# haltium_secure register map
Vendor: Nordic Semiconductor; Series: nRFHaltium; File version: 1
CPU: CM33 r0p4, little endian, MPU, FPU, 3 interrupt priority bits, 480 interrupts
Registers are 32-bit, read-write, reset 0x0 unless marked. A register's access mark holds for its fields unless they carry their own. Offsets are from the block's base; [hi:lo] are bit positions; lines under a group give offsets from that group; {n}, {i} and the like mark numbered series; 'fields as' and 'values as' point back to an identical list.

## CACHE0INFO_S — CACHEINFO 0
Base 0xE0F08000
Same registers: CACHE1INFO_S 0xE0F0C000
{0x0+8i} SET[{i}] (i=0..255) group — Unspecified
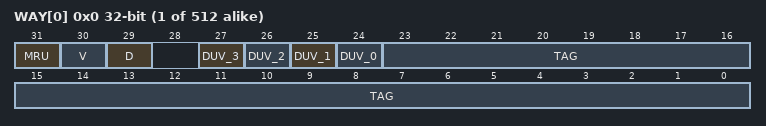
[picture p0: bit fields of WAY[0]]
  {0x0+4j} WAY[{j}] (j=0..1) — Description collection: Cache information for SET[n], WAY[o].
    [31] MRU ro — Most recently used way.
      0=Way0 was most recently used; 1=Way1 was most recently used
    [30] V ro — Line valid bit.
      0=Invalid cache line; 1=Valid cache line
    [29] D ro — Line dirty bit.
      0=Clean cache line; 1=Dirty cache line
    [n+24] DUV_{n} (n=0..3) — Data unit valid info.
      0=Invalid data unit; 1=Valid data unit
    [23:0] TAG — Cache tag.

## RAMC00_NS — RAM Controller 0
Base 0x41004000
Same registers: ROMC00_NS 0x41005000, RAMC00_S 0x51004000, ROMC00_S 0x51005000
0x100 EVENTS_ERRORFIX — ECC detected fixable (one bit) error in read data from RAM.
  [0] EVENTS_ERRORFIX
    0=NotGenerated (Event not generated); 1=Generated (Event generated)
0x104 EVENTS_ERRORNONFIX — ECC detected non-fixable (multiple bits) error in read data from RAM.
  [0] EVENTS_ERRORNONFIX
    values as EVENTS_ERRORFIX.EVENTS_ERRORFIX
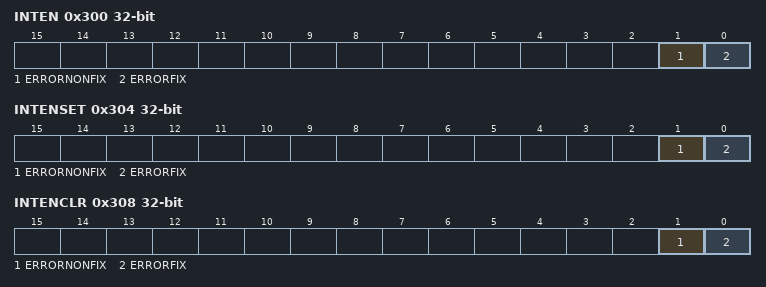
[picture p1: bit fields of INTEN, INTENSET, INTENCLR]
0x300 INTEN — Enable or disable interrupt
  [1] ERRORNONFIX — Enable or disable interrupt for event ERRORNONFIX
    0=Disabled; 1=Enabled
  [0] ERRORFIX — Enable or disable interrupt for event ERRORFIX
    0=Disabled; 1=Enabled
0x304 INTENSET — Enable interrupt
  [1] ERRORNONFIX — Write '1' to enable interrupt for event ERRORNONFIX
    on read: 0=Disabled (Read: Disabled); 1=Enabled (Read: Enabled) | on write: 1=Set (Enable)
  [0] ERRORFIX — Write '1' to enable interrupt for event ERRORFIX
    values as ERRORNONFIX
0x308 INTENCLR — Disable interrupt
  [1] ERRORNONFIX — Write '1' to disable interrupt for event ERRORNONFIX
    on read: 0=Disabled (Read: Disabled); 1=Enabled (Read: Enabled) | on write: 1=Clear (Disable)
  [0] ERRORFIX — Write '1' to disable interrupt for event ERRORFIX
    values as ERRORNONFIX
0x400 FIXADDR ro — Address of the last fixable error detected by the ECC.
  [31:0] ADDR — Address of the last fixable error.
0x404 NONFIXADDR ro — Address of the last non-fixable error detected by the ECC.
  [31:0] ADDR — Address of the last fixable error.
0x500 WAITSTATES — Waitstates for read.
  [2:0] WAITSTATES — Waitstates for read from RAM or ROM.
0x600 SECBASE — Base address for secure access area.
  [31:0] ADDR — Base address
0x604 SECENABLE — Enable secure access restrictions.
  [0] ENABLE — Enable secure access restrictions
    0=Disable (Secure access restrictions disabled); 1=Enable (Secure access restrictions enabled)

## CPUCONF_NS — CPU Configuration 0
Base 0x41011000
Same registers: CPUCONF_S 0x51011000
0x00 TASKS_ERASECACHE wo — Erase the caches used by the CPU.
  [0] TASKS_ERASECACHE
    1=Trigger task
0x500 INITSVTOR — Initial value of the secure VTOR (Vector Table Offset Register) after CPU reset.
  [31:0] INITSVTOR — Initial value of the VTOR.
0x504 INITNSVTOR — Initial value of the non-secure VTOR (Vector Table Offset Register).
  [31:0] INITNSVTOR — Initial value of the VTOR.
0x508 CPUSTART — Enable for starting the CPU
  [0] EN — Enable to start the CPU.
    0=Stopped (CPU stopped.); 1=Started (CPU started.)
0x50C CPUWAIT — Enable for the CPU wait.
  [0] EN — Enable to the CPU wait.
    0=Disabled (CPU is not waiting.); 1=Enabled (CPU is waiting.)

## TAMPC_S — Tamper controller
Base 0x51016000
0x100 EVENTS_TAMPER — Tamper controller detected an error.
  [0] EVENTS_TAMPER
    0=NotGenerated (Event not generated); 1=Generated (Event generated)
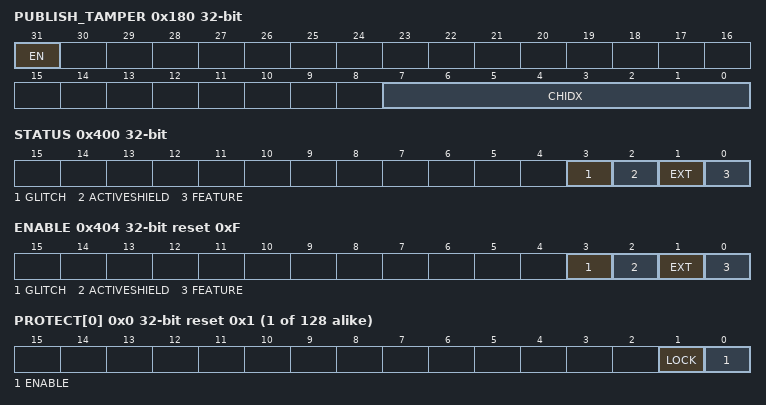
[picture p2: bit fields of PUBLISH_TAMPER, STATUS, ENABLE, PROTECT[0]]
0x180 PUBLISH_TAMPER — Publish configuration for event TAMPER
  [31] EN
    0=Disabled (Disable publishing); 1=Enabled (Enable publishing)
  [7:0] CHIDX — DPPI channel that event TAMPER will publish to
0x300 INTEN — Enable or disable interrupt
  [0] TAMPER — Enable or disable interrupt for event TAMPER
    0=Disabled; 1=Enabled
0x304 INTENSET — Enable interrupt
  [0] TAMPER — Write '1' to enable interrupt for event TAMPER
    on read: 0=Disabled (Read: Disabled); 1=Enabled (Read: Enabled) | on write: 1=Set (Enable)
0x308 INTENCLR — Disable interrupt
  [0] TAMPER — Write '1' to disable interrupt for event TAMPER
    on read: 0=Disabled (Read: Disabled); 1=Enabled (Read: Enabled) | on write: 1=Clear (Disable)
0x30C INTPEND ro — Pending interrupts
  [0] TAMPER — Read pending status of interrupt for event TAMPER
    on read: 0=NotPending (Read: Not pending); 1=Pending (Read: Pending)
0x400 STATUS — The tamper controller status.
  [all] fields
    0=NotDetected; 1=Detected
  [3] GLITCH — Glitch detector detected an error.
  [2] ACTIVESHIELD — Active shield detector detected an error.
  [1] EXT — External tamper detector detected an error.
  [0] FEATURE — Error detected for the feature protection.
0x404 ENABLE reset 0xF — Enable the tamper detectors.
  [all] fields
    0=Disabled; 1=Enabled
  [3] GLITCH — Enable glitch detector.
  [2] ACTIVESHIELD — Enable active shield detector.
  [1] EXT — Enable external tamper detector.
  [0] FEATURE — Enable the detector for feature.
0x408 FEATURE group — Unspecified
  {0x0+4j} PROTECT[{j}] (j=0..127) reset 0x1 — Description collection: Enable the feature protection n.
    [1] LOCK — Enable lock for the enable protection.
      0=Disabled (Lock disabled.); 1=Enabled (Lock enabled.)
    [0] ENABLE — Enable protection.
      0=Disabled (Protection disabled); 1=Enabled (Protection enabled)
0x608 ACTIVESHIELD group — Unspecified
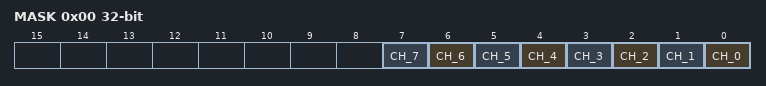
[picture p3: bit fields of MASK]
  0x00 MASK — Active shield channel mask.
    [all] fields
      1=Mask (channel masked); 0=Unmask (channel unmasked)
    [n] CH_{n} (n=0..7) — Channel mask.
0x60C GLITCH group — Unspecified
  0x00 CONFIG reset 0x3 — Configuration for the glitch detector.
    [1:0] EXTRADELAY — Extra delay configuration.
